# myChip register map
Vendor: ARM Ltd.; Series: ARMCM3; File version: 1.2
CPU: CM3 r2p1, little endian, no MPU, no FPU, 3 interrupt priority bits
Registers are 32-bit, read-write, reset 0x0 unless marked. A register's access mark holds for its fields unless they carry their own. Offsets are from the block's base; [hi:lo] are bit positions; {n}, {i} and the like mark numbered series.

## TMR3
Base 0x4002A000
Same registers: TMR4 0x4002B000
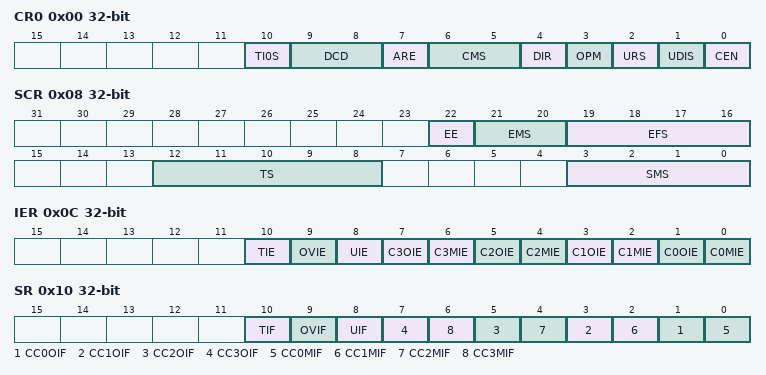
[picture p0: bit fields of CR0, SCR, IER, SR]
0x00 CR0 — TMRx Control Register0
  [10] TI0S — TI0输入选择(TI0 Input Selection)
  [9:8] DCD — 时钟分频(Clock Division)
  [7] ARE — 自动重载使能(AutoReload Enable)
  [6:5] CMS — 中心对齐模式(Center-Aligned Mode Selection)
  [4] DIR — 计数方向(Counter Direction)
  [3] OPM — 单脉冲模式(One Pulse Mode)
  [2] URS — 更新事件源(Update Request Source)
  [1] UDIS — 更新禁止位(Update Disable)
  [0] CEN — 计数器使能位(Counter Enable)
0x04 CR1 — TMRx Control Register1
  [2:0] MMS — 主模式选择(Master Mode Selection)
0x08 SCR — TMRx Slave Control Register
  [22] EE — ETR控制模式选择(ETR Mode Selection)
  [21:20] EMS — ETR模式选择(ETR Mode Selection)
  [19:16] EFS — ETR滤波选择(ETR Filter Selection)
  [12:8] TS — 触发选择(Trigger Selection)
  [3:0] SMS — 从模式选择(Slave Mode Selection)
0x0C IER — TMRx Interrupt Enable Register
  [10] TIE — 触发中断使能(Trigger Interrupt Enable)
  [9] OVIE — 计数上溢中断使能(Overflow Interrupt Enable)
  [8] UIE — 更新中断使能(Update Interrupt Enable)
  [2n+1] C{n}OIE (n=0..3) — CH{n}重复捕获中断使能(CH{n} OverCapture Interrupt Enable)
  [2n] C{n}MIE (n=0..3) — CH{n}比较中断使能(CH{n} Capture/Compare Interrupt Enable)
0x10 SR — TMRx Status Register
  [10] TIF — 触发中断标志(Trigger Interrupt Flag)
  [9] OVIF — 计数器上溢中断标志位(Counter Overflow Interrupt Flag)
  [8] UIF — 更新中断标志(Update Interrupt Flag)
  [2n+1] CC{n}OIF (n=0..3) — CC{n}重复捕获成功中断标志位(CC{n} OverCapture Interrupt Flag)
  [2n] CC{n}MIF (n=0..3) — CC{n}比较成功中断标志位(CC{n} Capture/Compare Interrupt Flag)
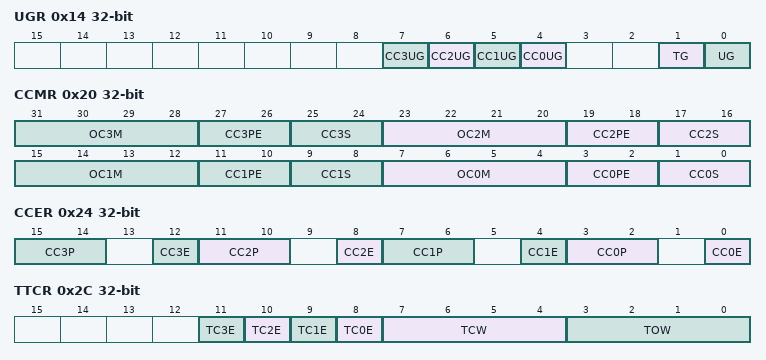
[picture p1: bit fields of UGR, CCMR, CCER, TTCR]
0x14 UGR — TMRx Update Generation Register
  [n+4] CC{n}UG (n=0..3) — CC{n}捕获/比较更新事件生成(CC{n} Capture/Compare Update Generation)
  [1] TG — 触发事件生成(Trigger Generation)
  [0] UG — 更新事件生成(Update Generation)
0x20 CCMR — TMRx Capture Compare Mode Register
  [8n+7:8n+4] OC{n}M (n=0..3) — CC{n}输入滤波/输出比较模式选择(CC{n} Input Filter/Output Compare Mode)
  [8n+3:8n+2] CC{n}PE (n=0..3) — CC{n}输入捕获分频/比较自动加载使能(CC{n} Compare Auto-Realod Enable)
  [8n+1:8n] CC{n}S (n=0..3) — CC{n}捕获/比较方向选择(CC{n} Capture Compare Selection)
0x24 CCER — TMRx Capture Compare Enable Register
  [4n+3:4n+2] CC{n}P (n=0..3) — CC{n}捕获/比较极性选择(CC{n} Compare/Capture Polarity)
  [4n] CC{n}E (n=0..3) — CC{n}捕获/比较通道使能(CC{n} Capture/Compare Enable)
0x2C TTCR — TMRx Trigger Cycles Register
  [n+8] TC{n}E (n=0..3) — TRGO CH{n}输出使能(Trigger CH{n} Enable)
  [7:4] TCW — TRGCC脉冲宽度控制(Trigger Compare/Caputre Width)
  [3:0] TOW — TRGO脉冲宽度控制(Trigger Output Width)
0x30 CPR — TMRx Counter Period Register
  [31:0] CPV — 计数周期值(Counter Period Value)
0x38 PSCR — TMRx Prescaler Register
  [15:0] PSC — 预分频寄存器（Prescaler Value)
0x3C CNTR — TMRx Counter Register
  [31:0] CNT — 定时器计数值(Counter Value)
{0x50+4i} CC{i}R (i=0..3) — TMRx Capture Compare Register{i}
  [31:0] CC{i}V — CC{i}捕获/比较值(CC{i} Capture/Compare Value)
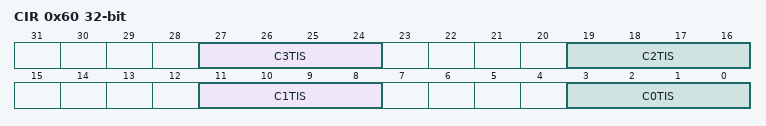
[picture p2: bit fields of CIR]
0x60 CIR — TMRx Capture Input Register
  [27:24] C3TIS — CH3触发输入选择(CH3 Capture Input Selection)
  [19:16] C2TIS — CH2触发输入选择(CH2 Capture Input Selection)
  [11:8] C1TIS — CH1触发输入选择(CH1 Capture Input Selection)
  [3:0] C0TIS — CH0触发输入选择(CH0 Trigger Input Selection)

## GPIOA
Base 0x40024000
Same registers: GPIOB 0x40025000, GPIOC 0x40026000, GPIOD 0x40027000, GPIOE 0x40028000, GPIOF 0x40029000
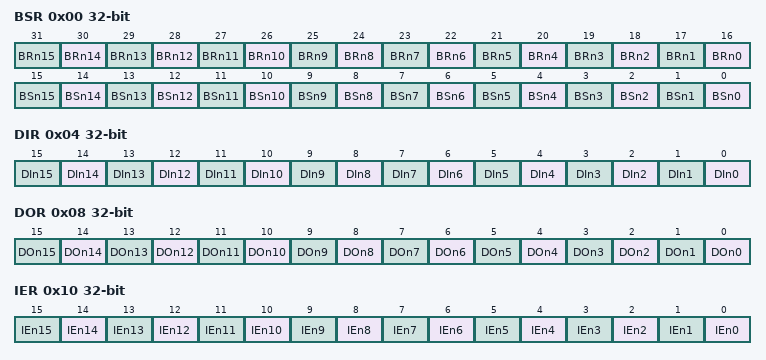
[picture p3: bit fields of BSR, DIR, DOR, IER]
0x00 BSR — GPIOx Bit Set/Reset Register
  [n+16] BRn{n} (n=0..15) — GPIO端口x引脚n输出复位(GPIO Bit Reset Control)
  [n] BSn{n} (n=0..15) — GPIO端口x引脚n输出置位(GPIO Bit Set Control)
0x04 DIR — GPIOx Data Input Register
  [n] DIn{n} (n=0..15) ro — GPIO端口x引脚n输入数据寄存器(GPIO Data Input)
0x08 DOR — GPIOx Data Output Register
  [n] DOn{n} (n=0..15) — GPIO端口x引脚n输出数据寄存器(GPIO Data Output)
0x10 IER — GPIOx Interrupt Enable Register
  [n] IEn{n} (n=0..15) — GPIO端口x引脚n中断使能位(GPIO Interrupt Enable)
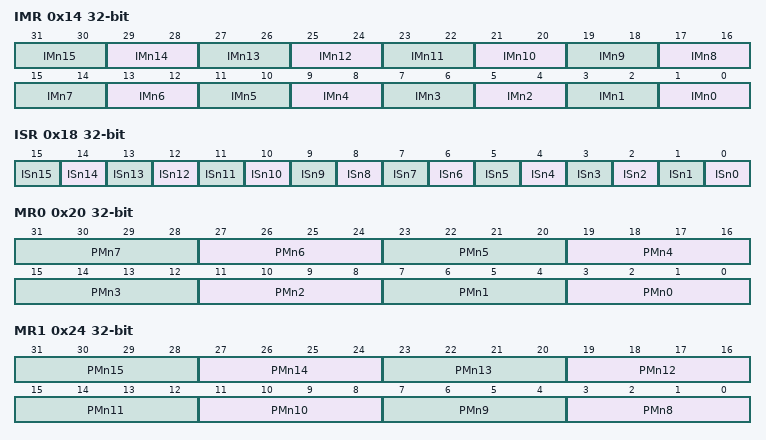
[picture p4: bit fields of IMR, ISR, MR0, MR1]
0x14 IMR — GPIOx Interrupt Mode Register
  [2n+1:2n] IMn{n} (n=0..15) — GPIO端口x引脚n中断模式选择位(GPIO Interrupt Mode)
0x18 ISR — GPIOx Pending Register
  [n] ISn{n} (n=0..15) — GPIO端口x引脚n中断标志位(GPIO Interrupt Flag)
0x20 MR0 — GPIOx Mux Register0
  [4n+3:4n] PMn{n} (n=0..7) — GPIO端口x引脚n功能复用配置寄存器(GPIO MUX Selection)
0x24 MR1 — GPIOx Mux Register1
  [4n-29:4n-32] PMn{n} (n=8..15) — GPIO端口x引脚n功能复用配置寄存器(GPIO MUX Selection)
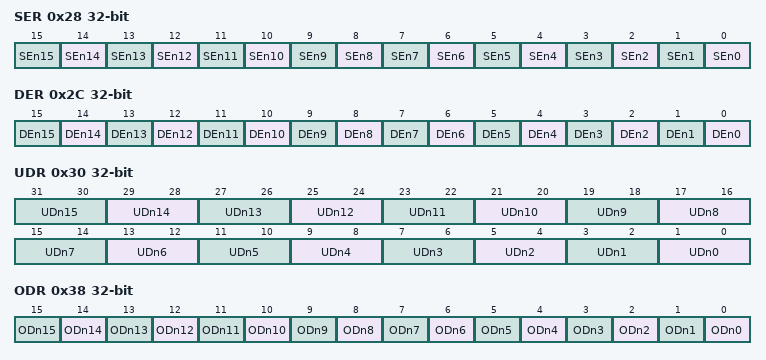
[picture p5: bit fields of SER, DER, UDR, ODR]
0x28 SER — GPIOx Sync Register
  [n] SEn{n} (n=0..15) — GPIO端口x引脚n同步使能控制位(GPIO Sync Enable)
0x2C DER — GPIOx Debounce Register
  [n] DEn{n} (n=0..15) — GPIO端口x引脚n消抖使能控制位(GPIO Debounce Enable)
0x30 UDR — GPIOx Pull Up/Down Register
  [2n+1:2n] UDn{n} (n=0..15) — GPIO端口x引脚n上下拉使能控制位(GPIO Pull Up/Down Enable)
0x38 ODR — GPIOx Open Drain Register
  [n] ODn{n} (n=0..15) — GPIO端口x引脚n开漏使能控制位(GPIO Open Drain Enable)
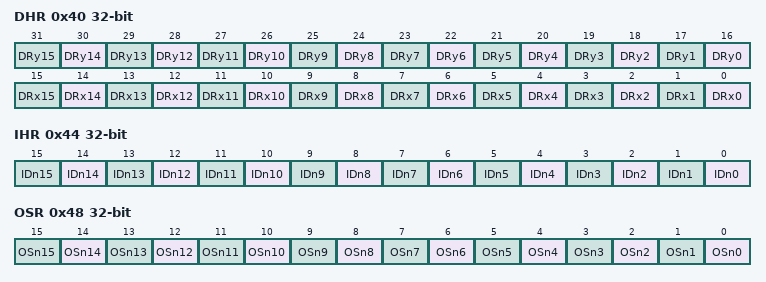
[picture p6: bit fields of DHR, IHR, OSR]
0x40 DHR — GPIOx Driver Register
  [n+16] DRy{n} (n=0..15) — GPIO端口x引脚n驱动能力选择y(GPIO Drivery Selection)
  [n] DRx{n} (n=0..15) — GPIO端口x引脚n驱动能力选择x(GPIO Driverx Selection)
0x44 IHR — GPIOx Hysteresis Register
  [n] IDn{n} (n=0..15) — GPIO端口x引脚n输入迟滞使能控制位(GPIO Input Hysteresis Enable)
0x48 OSR — GPIOx Slew Register
  [n] OSn{n} (n=0..15) — GPIO端口x引脚n输出速率选择(GPIO Slew Selection)
